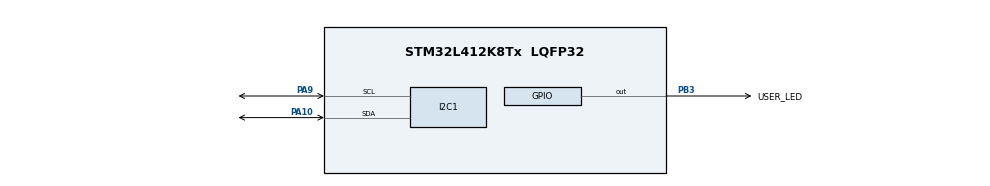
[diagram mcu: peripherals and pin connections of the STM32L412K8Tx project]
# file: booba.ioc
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Mcu.Family=STM32L4
PB3\ (JTDO/TRACESWO).GPIO_Label=USER_LED
RCC.MSI_VALUE=4000000
RCC.VCOOutputFreq_Value=32000000
PA10.Mode=I2C
RCC.ADCFreq_Value=4000000
VP_RTC_VS_RTC_Activate.Mode=RTC_Enabled
Mcu.Name=STM32L412K8Tx
Mcu.Package=LQFP32
ProjectManager.StackSize=0x400
PA9.Mode=I2C
PA10.Signal=I2C1_SDA
VP_RTC_VS_RTC_Calendar.Mode=RTC_Calendar
ProjectManager.HeapSize=0x200
PB3\ (JTDO/TRACESWO).Signal=GPIO_Output
ProjectManager.TargetToolchain=Makefile
RCC.HSI_VALUE=16000000
NVIC.PriorityGroup=NVIC_PRIORITYGROUP_4
PA9.Signal=I2C1_SCL
RCC.USBFreq_Value=4000000
RCC.LSE_VALUE=32768
RCC.HSI48_VALUE=48000000
RCC.HSE_VALUE=8000000
board=custom

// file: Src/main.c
/* USER CODE BEGIN Header */
/**
  ******************************************************************************
  * @file           : main.c
  * @brief          : Main program body
  ******************************************************************************
  * @attention
  *
  * <h2><center>&copy; Copyright (c) 2020 STMicroelectronics.
  * All rights reserved.</center></h2>
  *
  * This software component is licensed by ST under BSD 3-Clause license,
  * the "License"; You may not use this file except in compliance with the
  * License. You may obtain a copy of the License at:
  *                        opensource.org/licenses/BSD-3-Clause
  *
  ******************************************************************************
  */
/* USER CODE END Header */

#include "main.h"

/* USER CODE BEGIN Includes */
#include "sched.h"
#include "gui.h"
#include "ssd1306.h"
#include "ssd1306_fonts.h"
#include "ssd1306_test.h"
/* USER CODE END Includes */

I2C_HandleTypeDef hi2c1;

RTC_HandleTypeDef hrtc;

void SystemClock_Config(void);
static void MX_GPIO_Init(void);
static void MX_I2C1_Init(void);
static void MX_RTC_Init(void);

int main(void)
{
  /* USER CODE BEGIN 1 */
  char str[32];
  static uint8_t cnt = 0;

  static uint8_t  sched_flag_10ms   = 0;
	static uint8_t  sched_flag_100ms  = 0;
	static uint8_t  sched_flag_200ms  = 0;
	static uint8_t  sched_flag_500ms  = 0;
	static uint8_t  sched_flag_1000ms = 0;

  sched_init();
	sched_schedule(10,   &sched_flag_10ms);
	sched_schedule(100,  &sched_flag_100ms);
	sched_schedule(200,  &sched_flag_200ms);
	sched_schedule(500,  &sched_flag_500ms);
	sched_schedule(1000, &sched_flag_1000ms);
  /* USER CODE END 1 */

  /* MCU Configuration--------------------------------------------------------*/

  /* Reset of all peripherals, Initializes the Flash interface and the Systick. */
  HAL_Init();

  /* Configure the system clock */
  SystemClock_Config();

  /* Initialize all configured peripherals */
  MX_GPIO_Init();
  MX_I2C1_Init();
  MX_RTC_Init();
  /* USER CODE BEGIN 2 */
  gui_init();
  /* USER CODE END 2 */

  /* Infinite loop */
  while (1)
  {

    /* USER CODE BEGIN 3 */
    sched_process();

		if (sched_flag_10ms) {
			sched_schedule(10,   &sched_flag_10ms);
		}
		if (sched_flag_100ms)	{
			sched_schedule(100,   &sched_flag_100ms);
      HAL_GPIO_TogglePin(USER_LED_GPIO_Port, USER_LED_Pin);
      gui_process();
		}
		if (sched_flag_1000ms) {
			sched_schedule(1000,   &sched_flag_1000ms);
      // sprintf(str, "CNT = %d", cnt++);
      // gui_draw_string(str, eGUI_ALIGNMENT_X_LEFT | eGUI_ALIGNMENT_Y_UP, 0);
		}

  }
  /* USER CODE END 3 */
}

void SystemClock_Config(void)
{
  RCC_OscInitTypeDef RCC_OscInitStruct = {0};
  RCC_ClkInitTypeDef RCC_ClkInitStruct = {0};
  RCC_PeriphCLKInitTypeDef PeriphClkInit = {0};

  /** Configure the main internal regulator output voltage
  */
  if (HAL_PWREx_ControlVoltageScaling(PWR_REGULATOR_VOLTAGE_SCALE1) != HAL_OK)
  {
    Error_Handler();
  }
  /** Initializes the CPU, AHB and APB busses clocks
  */
  RCC_OscInitStruct.OscillatorType = RCC_OSCILLATORTYPE_LSI|RCC_OSCILLATORTYPE_MSI;
  RCC_OscInitStruct.LSIState = RCC_LSI_ON;
  RCC_OscInitStruct.MSIState = RCC_MSI_ON;
  RCC_OscInitStruct.MSICalibrationValue = 0;
  RCC_OscInitStruct.MSIClockRange = RCC_MSIRANGE_6;
  RCC_OscInitStruct.PLL.PLLState = RCC_PLL_NONE;
  if (HAL_RCC_OscConfig(&RCC_OscInitStruct) != HAL_OK)
  {
    Error_Handler();
  }
  /** Initializes the CPU, AHB and APB busses clocks
  */
  RCC_ClkInitStruct.ClockType = RCC_CLOCKTYPE_HCLK|RCC_CLOCKTYPE_SYSCLK
                              |RCC_CLOCKTYPE_PCLK1|RCC_CLOCKTYPE_PCLK2;
  RCC_ClkInitStruct.SYSCLKSource = RCC_SYSCLKSOURCE_MSI;
  RCC_ClkInitStruct.AHBCLKDivider = RCC_SYSCLK_DIV1;
  RCC_ClkInitStruct.APB1CLKDivider = RCC_HCLK_DIV1;
  RCC_ClkInitStruct.APB2CLKDivider = RCC_HCLK_DIV1;

  if (HAL_RCC_ClockConfig(&RCC_ClkInitStruct, FLASH_LATENCY_0) != HAL_OK)
  {
    Error_Handler();
  }
  PeriphClkInit.PeriphClockSelection = RCC_PERIPHCLK_RTC|RCC_PERIPHCLK_I2C1;
  PeriphClkInit.I2c1ClockSelection = RCC_I2C1CLKSOURCE_PCLK1;
  PeriphClkInit.RTCClockSelection = RCC_RTCCLKSOURCE_LSI;
  if (HAL_RCCEx_PeriphCLKConfig(&PeriphClkInit) != HAL_OK)
  {
    Error_Handler();
  }
}

static void MX_I2C1_Init(void)
{

  hi2c1.Instance = I2C1;
  hi2c1.Init.Timing = 0x00000E14;
  hi2c1.Init.OwnAddress1 = 0;
  hi2c1.Init.AddressingMode = I2C_ADDRESSINGMODE_7BIT;
  hi2c1.Init.DualAddressMode = I2C_DUALADDRESS_DISABLE;
  hi2c1.Init.OwnAddress2 = 0;
  hi2c1.Init.OwnAddress2Masks = I2C_OA2_NOMASK;
  hi2c1.Init.GeneralCallMode = I2C_GENERALCALL_DISABLE;
  hi2c1.Init.NoStretchMode = I2C_NOSTRETCH_DISABLE;
  if (HAL_I2C_Init(&hi2c1) != HAL_OK)
  {
    Error_Handler();
  }
  /** Configure Analogue filter
  */
  if (HAL_I2CEx_ConfigAnalogFilter(&hi2c1, I2C_ANALOGFILTER_ENABLE) != HAL_OK)
  {
    Error_Handler();
  }
  /** Configure Digital filter
  */
  if (HAL_I2CEx_ConfigDigitalFilter(&hi2c1, 0) != HAL_OK)
  {
    Error_Handler();
  }

}

static void MX_RTC_Init(void)
{

  RTC_TimeTypeDef sTime = {0};
  RTC_DateTypeDef sDate = {0};

  /** Initialize RTC Only
  */
  hrtc.Instance = RTC;
  hrtc.Init.HourFormat = RTC_HOURFORMAT_24;
  hrtc.Init.AsynchPrediv = 127;
  hrtc.Init.SynchPrediv = 255;
  hrtc.Init.OutPut = RTC_OUTPUT_DISABLE;
  hrtc.Init.OutPutRemap = RTC_OUTPUT_REMAP_NONE;
  hrtc.Init.OutPutPolarity = RTC_OUTPUT_POLARITY_HIGH;
  hrtc.Init.OutPutType = RTC_OUTPUT_TYPE_OPENDRAIN;
  hrtc.Init.OutPutPullUp = RTC_OUTPUT_PULLUP_NONE;
  if (HAL_RTC_Init(&hrtc) != HAL_OK)
  {
    Error_Handler();
  }

  /** Initialize RTC and set the Time and Date
  */
  sTime.Hours = 0x0;
  sTime.Minutes = 0x0;
  sTime.Seconds = 0x0;
  sTime.DayLightSaving = RTC_DAYLIGHTSAVING_NONE;
  sTime.StoreOperation = RTC_STOREOPERATION_RESET;
  if (HAL_RTC_SetTime(&hrtc, &sTime, RTC_FORMAT_BCD) != HAL_OK)
  {
    Error_Handler();
  }
  sDate.WeekDay = RTC_WEEKDAY_MONDAY;
  sDate.Month = RTC_MONTH_JANUARY;
  sDate.Date = 0x1;
  sDate.Year = 0x0;

  if (HAL_RTC_SetDate(&hrtc, &sDate, RTC_FORMAT_BCD) != HAL_OK)
  {
    Error_Handler();
  }

}

static void MX_GPIO_Init(void)
{
  GPIO_InitTypeDef GPIO_InitStruct = {0};

  /* GPIO Ports Clock Enable */
  __HAL_RCC_GPIOA_CLK_ENABLE();
  __HAL_RCC_GPIOB_CLK_ENABLE();

  /*Configure GPIO pin Output Level */
  HAL_GPIO_WritePin(USER_LED_GPIO_Port, USER_LED_Pin, GPIO_PIN_RESET);

  /*Configure GPIO pin : USER_LED_Pin */
  GPIO_InitStruct.Pin = USER_LED_Pin;
  GPIO_InitStruct.Mode = GPIO_MODE_OUTPUT_PP;
  GPIO_InitStruct.Pull = GPIO_NOPULL;
  GPIO_InitStruct.Speed = GPIO_SPEED_FREQ_LOW;
  HAL_GPIO_Init(USER_LED_GPIO_Port, &GPIO_InitStruct);

}

void Error_Handler(void)
{
}

/************************ (C) COPYRIGHT STMicroelectronics *****END OF FILE****/
